AUTOSAR XML (schema 4-0-3)
package /ComponentTypes
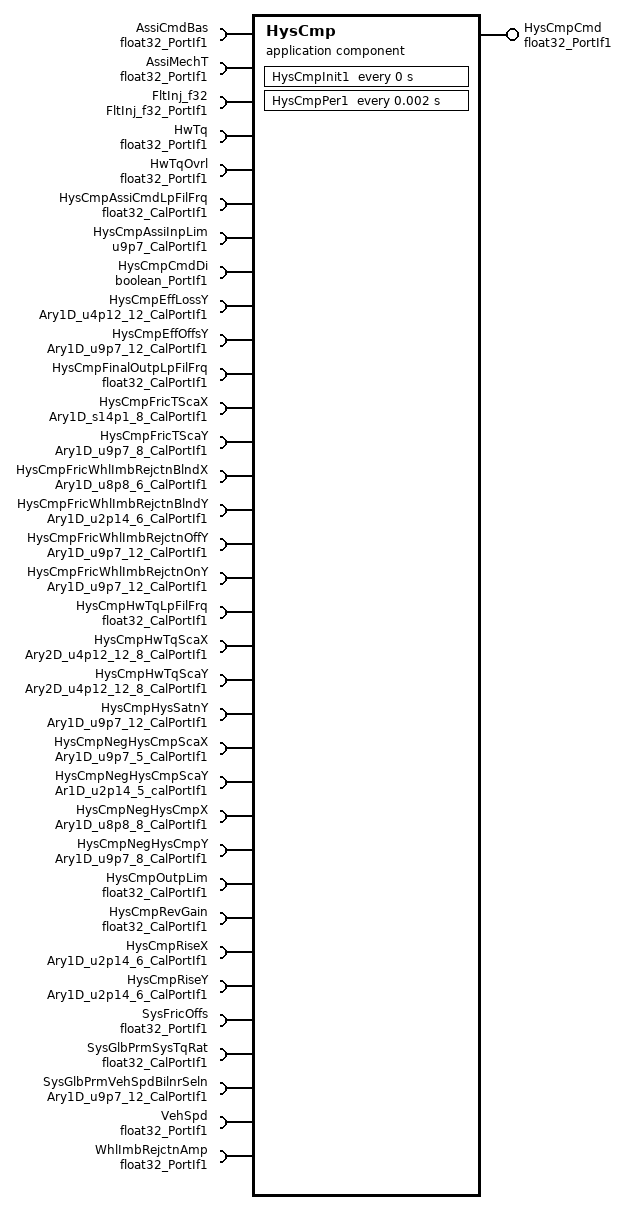
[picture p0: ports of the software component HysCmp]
  application sw component type HysCmp
    provide port HysCmpCmd: nonqueued-sender-com-spec{data-element=Val, init-value=0}, provided-interface=float32_PortIf1
    34 x require port:
      AssiCmdBas: nonqueued-receiver-com-spec{data-element=Val, filter=data-filter-type=ALWAYS, init-value=0}, required-interface=float32_PortIf1
      AssiMechT: nonqueued-receiver-com-spec{data-element=Val, filter=data-filter-type=ALWAYS, init-value=0}, required-interface=float32_PortIf1
      FltInj_f32: client-com-spec=Oper, required-interface=FltInj_f32_PortIf1
      HwTq: nonqueued-receiver-com-spec{data-element=Val, filter=data-filter-type=ALWAYS, init-value=0}, required-interface=float32_PortIf1
      HwTqOvrl: nonqueued-receiver-com-spec{data-element=Val, filter=data-filter-type=ALWAYS, init-value=0}, required-interface=float32_PortIf1
      HysCmpAssiCmdLpFilFrq: parameter-require-com-spec{init-value=50, parameter=Val}, required-interface=float32_CalPortIf1
      HysCmpAssiInpLim: parameter-require-com-spec{init-value=45056, parameter=Val}, required-interface=u9p7_CalPortIf1
      HysCmpCmdDi: nonqueued-receiver-com-spec{data-element=Logl, filter=data-filter-type=ALWAYS, init-value=0}, required-interface=boolean_PortIf1
      HysCmpEffLossY: parameter-require-com-spec{init-value=12 x 0, parameter=Ary1D}, required-interface=Ary1D_u4p12_12_CalPortIf1
      HysCmpEffOffsY: parameter-require-com-spec{init-value=12 x 0, parameter=Ary1D}, required-interface=Ary1D_u9p7_12_CalPortIf1
      HysCmpFinalOutpLpFilFrq: parameter-require-com-spec{init-value=50, parameter=Val}, required-interface=float32_CalPortIf1
      HysCmpFricTScaX: parameter-require-com-spec{init-value=[-80, -60, -40, -20, 0, 50, 100, 160], parameter=Ary1D}, required-interface=Ary1D_s14p1_8_CalPortIf1
      HysCmpFricTScaY: parameter-require-com-spec{init-value=8 x 128, parameter=Ary1D}, required-interface=Ary1D_u9p7_8_CalPortIf1
      HysCmpFricWhlImbRejctnBlndX: parameter-require-com-spec{init-value=[0, 51, 102, 154, 205, 256], parameter=Ary1D}, required-interface=Ary1D_u8p8_6_CalPortIf1
      HysCmpFricWhlImbRejctnBlndY: parameter-require-com-spec{init-value=6 x 0, parameter=Ary1D}, required-interface=Ary1D_u2p14_6_CalPortIf1
      HysCmpFricWhlImbRejctnOffY: parameter-require-com-spec{init-value=12 x 0, parameter=Ary1D}, required-interface=Ary1D_u9p7_12_CalPortIf1
      HysCmpFricWhlImbRejctnOnY: parameter-require-com-spec{init-value=12 x 0, parameter=Ary1D}, required-interface=Ary1D_u9p7_12_CalPortIf1
      HysCmpHwTqLpFilFrq: parameter-require-com-spec{init-value=50, parameter=Val}, required-interface=float32_CalPortIf1
      HysCmpHwTqScaX: parameter-require-com-spec{init-value=12 x [0, 815, 1634, 2458, 4096, 5730, 8192, 40960], parameter=Ary2D}, required-interface=Ary2D_u4p12_12_8_CalPortIf1
      HysCmpHwTqScaY: parameter-require-com-spec{init-value=12 x 8 x 4096, parameter=Ary2D}, required-interface=Ary2D_u4p12_12_8_CalPortIf1
      HysCmpHysSatnY: parameter-require-com-spec{init-value=12 x 1280, parameter=Ary1D}, required-interface=Ary1D_u9p7_12_CalPortIf1
      HysCmpNegHysCmpScaX: parameter-require-com-spec{init-value=[0, 128, 256, 384, 512], parameter=Ary1D}, required-interface=Ary1D_u9p7_5_CalPortIf1
      HysCmpNegHysCmpScaY: parameter-require-com-spec{init-value=5 x 16384, parameter=Ary1D}, required-interface=Ar1D_u2p14_5_calPortIf1
      HysCmpNegHysCmpX: parameter-require-com-spec{init-value=[0, 26, 51, 102, 154, 205, 230, 256], parameter=Ary1D}, required-interface=Ary1D_u8p8_8_CalPortIf1
      HysCmpNegHysCmpY: parameter-require-com-spec{init-value=8 x 0, parameter=Ary1D}, required-interface=Ary1D_u9p7_8_CalPortIf1
      HysCmpOutpLim: parameter-require-com-spec{init-value=16, parameter=Val}, required-interface=float32_CalPortIf1
      HysCmpRevGain: parameter-require-com-spec{init-value=6, parameter=Val}, required-interface=float32_CalPortIf1
      HysCmpRiseX: parameter-require-com-spec{init-value=[0, 1556, 2097, 2540, 2982, 3277], parameter=Ary1D}, required-interface=Ary1D_u2p14_6_CalPortIf1
      HysCmpRiseY: parameter-require-com-spec{init-value=[0, 9863, 12878, 14811, 15974, 16384], parameter=Ary1D}, required-interface=Ary1D_u2p14_6_CalPortIf1
      SysFricOffs: nonqueued-receiver-com-spec{data-element=Val, filter=data-filter-type=ALWAYS, init-value=0}, required-interface=float32_PortIf1
      SysGlbPrmSysTqRat: parameter-require-com-spec{init-value=20, parameter=Val}, required-interface=float32_CalPortIf1
      SysGlbPrmVehSpdBilnrSeln: parameter-require-com-spec{init-value=[0, 640, 1920, 3840, 7680, 10240, 12800, 15360, 19200, 23040, 25600, 28160], parameter=Ary1D}, required-interface=Ary1D_u9p7_12_CalPortIf1
      VehSpd: nonqueued-receiver-com-spec{data-element=Val, filter=data-filter-type=ALWAYS, init-value=0}, required-interface=float32_PortIf1
      WhlImbRejctnAmp: nonqueued-receiver-com-spec{data-element=Val, filter=data-filter-type=ALWAYS, init-value=0}, required-interface=float32_PortIf1
    behavior HysCmp_InternalBehavior
      ar-typed-per-instance-memorys:
        16 x data, all with sw-calibration-access=READ-ONLY:
          AssiCmdLpFil: type=FilLpRec1
          dHysCmpAssiCmdFild: type=float32
          dHysCmpAvl: type=float32
          dHysCmpEffCmpTq: type=float32
          dHysCmpFric: type=float32
          dHysCmpHwTqFild: type=float32
          dHysCmpNegAvl: type=float32
          dHysCmpPosAvl: type=float32
          dHysCmpRawVal: type=float32
          dHysCmpRiseYFac: type=float32
          FinalOutpLpFil: type=FilLpRec1
          HwTqLpFil: type=FilLpRec1
          PrevAssiCmdFildVal: type=float32
          PrevHwTqFildVal: type=float32
          PrevRiseX: type=float32
          PrevRiseY: type=float32
      timing event HysCmp_InitEvent: start-on-event=HysCmpInit1, period=0
      timing event TMT_HysCmpPer1: start-on-event=HysCmpPer1, period=0.002
      runnable HysCmpInit1
      runnable HysCmpPer1
        data-receive-point-by-arguments:
          8 x access:
            REC_AssiCmdBas_Val: accessed-variable=AssiCmdBas.Val
            REC_AssiMechT_Val: accessed-variable=AssiMechT.Val
            REC_HwTq_Val: accessed-variable=HwTq.Val
            REC_HwTqOvrl_Val: accessed-variable=HwTqOvrl.Val
            REC_HysCmpCmdDi_Logl: accessed-variable=HysCmpCmdDi.Logl
            REC_SysFricOffs_Val: accessed-variable=SysFricOffs.Val
            REC_VehSpd_Val: accessed-variable=VehSpd.Val
            REC_WhlImbRejctnAmp_Val: accessed-variable=WhlImbRejctnAmp.Val
        data-send-points:
          access SEND_HysCmpCmd_Val: accessed-variable=HysCmpCmd.Val
        sync call SC_FltInj_f32_Oper: operation=FltInj_f32.Oper, timeout=0
  swc implementation HysCmp_Implementation: behavior=HysCmp_InternalBehavior
    code-descriptors:
      code Default: artifact-descriptors=autosar-engineering-object={short-label=Default, category=SWSRC}
